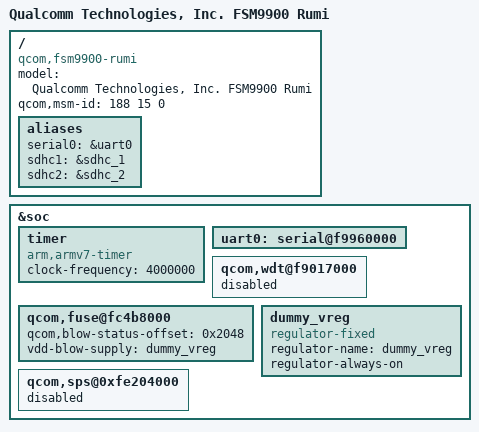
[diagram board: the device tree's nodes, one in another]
/* Copyright (c) 2013-2014, The Linux Foundation. All rights reserved.
 *
 * This program is free software; you can redistribute it and/or modify
 * it under the terms of the GNU General Public License version 2 and
 * only version 2 as published by the Free Software Foundation.
 *
 * This program is distributed in the hope that it will be useful,
 * but WITHOUT ANY WARRANTY; without even the implied warranty of
 * MERCHANTABILITY or FITNESS FOR A PARTICULAR PURPOSE.  See the
 * GNU General Public License for more details.
 */

/dts-v1/;

#include "fsm9900.dtsi"

/ {
	model = "Qualcomm Technologies, Inc. FSM9900 Rumi";
	compatible = "qcom,fsm9900-rumi", "qcom,fsm9900", "qcom,rumi";
	qcom,msm-id = <188 15 0>;

	aliases {
		serial0 = &uart0;
		sdhc1 = &sdhc_1; /* SDC1 eMMC slot */
		sdhc2 = &sdhc_2; /* SDC2 SD card slot */
	};
};

&soc {
	timer {
		compatible = "arm,armv7-timer";
		clock-frequency = <4000000>;
	};

	uart0: serial@f9960000 {
		status = "ok";
	};

	qcom,wdt@f9017000 {
		status = "disabled";
	};

	qcom,fuse@fc4b8000 {
		qcom,blow-status-offset = <0x2048>;
		vdd-blow-supply = <&dummy_vreg>;
		status = "ok";
	};

	dummy_vreg: dummy_vreg {
		compatible = "regulator-fixed";
		status = "ok";
		regulator-name = "dummy_vreg";
		regulator-always-on;
	};

	qcom,sps@0xfe204000 {
		status = "disabled";
	};
};
